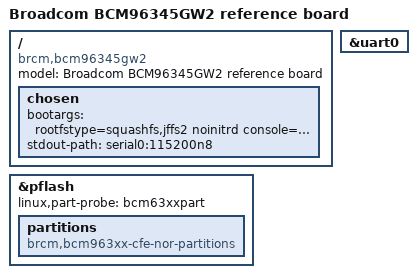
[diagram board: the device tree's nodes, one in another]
/dts-v1/;

#include "bcm6345.dtsi"

#include <dt-bindings/input/input.h>

/ {
	model = "Broadcom BCM96345GW2 reference board";
	compatible = "brcm,bcm96345gw2", "brcm,bcm6345";

	chosen {
		bootargs = "rootfstype=squashfs,jffs2 noinitrd console=ttyS0,115200";
		stdout-path = "serial0:115200n8";
	};
};

&pflash {
	status = "ok";

	linux,part-probe = "bcm63xxpart";

	partitions {
		compatible = "brcm,bcm963xx-cfe-nor-partitions";
	};
};

&uart0 {
	status = "ok";
};
